AUTOSAR XML (schema 314)
package /ComponentType
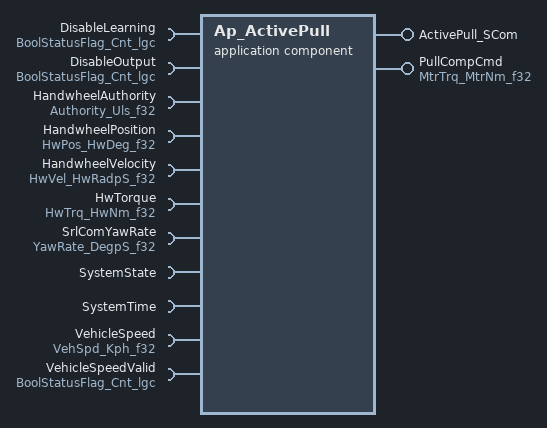
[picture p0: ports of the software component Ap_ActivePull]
  application software component type Ap_ActivePull
    provide port ActivePull_SCom: provided-interface=ActivePull_SCom
      provided-com-specs:
        operation=ReadParam, queue-length=1
        operation=Reset, queue-length=1
        operation=SetLTComp, queue-length=1
        operation=SetSTComp, queue-length=1
    provide port PullCompCmd: unqueued-sender-com-spec{data-element=MtrNm_f32, can-invalidate=false, init-value=D_ZERO_ULS_F32}, provided-interface=MtrTrq_MtrNm_f32
    11 x require port:
      DisableLearning: unqueued-receiver-com-spec{data-element=Cnt_lgc, init-value=D_FALSE_CNT_LGC}, required-interface=BoolStatusFlag_Cnt_lgc
      DisableOutput: unqueued-receiver-com-spec{data-element=Cnt_lgc, init-value=D_FALSE_CNT_LGC}, required-interface=BoolStatusFlag_Cnt_lgc
      HandwheelAuthority: unqueued-receiver-com-spec{data-element=Uls_f32, init-value=D_ZERO_ULS_F32}, required-interface=Authority_Uls_f32
      HandwheelPosition: unqueued-receiver-com-spec{data-element=HwDeg_f32, init-value=D_ZERO_ULS_F32}, required-interface=HwPos_HwDeg_f32
      HandwheelVelocity: unqueued-receiver-com-spec{data-element=HwRadpS_f32, init-value=D_ZERO_ULS_F32}, required-interface=HwVel_HwRadpS_f32
      HwTorque: unqueued-receiver-com-spec{data-element=HwNm_f32, init-value=D_ZERO_ULS_F32}, required-interface=HwTrq_HwNm_f32
      SrlComYawRate: unqueued-receiver-com-spec{data-element=DegpS_f32, init-value=D_ZERO_ULS_F32}, required-interface=YawRate_DegpS_f32
      SystemState: required-interface=SystemState
      SystemTime: required-interface=SystemTime
        required-com-specs:
          DtrmnElapsedTime_mS_u16
          DtrmnElapsedTime_mS_u32
          DtrmnElapsedTime_uS_u16
          DtrmnElapsedTime_uS_u32
          GetSystemTime_mS_u32
          GetSystemTime_uS_u32
      VehicleSpeed: unqueued-receiver-com-spec{data-element=Kph_f32, init-value=D_ZERO_ULS_F32}, required-interface=VehSpd_Kph_f32
      VehicleSpeedValid: unqueued-receiver-com-spec{data-element=Cnt_lgc, init-value=D_FALSE_CNT_LGC}, required-interface=BoolStatusFlag_Cnt_lgc
  internal behavior Ap_ActivePull_InternalBehavior: component=Ap_ActivePull
    4 x timing event:
      ActivePull_Init1_InitEvent: start-on-event=ActivePull_Init1, period=0
      TMT_ActivePull_Per1: mode-dependency=dependent-on-mode=[SystemState.Mode.DISABLE, SystemState.Mode.OFF, SystemState.Mode.WARMINIT], start-on-event=ActivePull_Per1, period=0.002
      TMT_ActivePull_Per2: mode-dependency=dependent-on-mode=SystemState.Mode.OFF, start-on-event=ActivePull_Per2, period=0.002
      TMT_ActivePull_Per3: mode-dependency=dependent-on-mode=[SystemState.Mode.DISABLE, SystemState.Mode.OFF, SystemState.Mode.WARMINIT], start-on-event=ActivePull_Per3, period=0.1
    4 x operation invoked event:
      OIT_ActivePull_SCom_ReadParam_ActivePull_SCom_ReadParam: start-on-event=ActivePull_SCom_ReadParam, operation=ActivePull_SCom.ReadParam
      OIT_ActivePull_SCom_Reset_ActivePull_SCom_Reset: start-on-event=ActivePull_SCom_Reset, operation=ActivePull_SCom.Reset
      OIT_ActivePull_SCom_SetLTComp_ActivePull_SCom_SetLTComp: start-on-event=ActivePull_SCom_SetLTComp, operation=ActivePull_SCom.SetLTComp
      OIT_ActivePull_SCom_SetSTComp_ActivePull_SCom_SetSTComp: start-on-event=ActivePull_SCom_SetSTComp, operation=ActivePull_SCom.SetSTComp
    mode switch event MST_ActivePull_Trns1_0: start-on-event=ActivePull_Trns1, activation=ENTRY, mode=SystemState.Mode.OPERATE
    port-api-options:
      enable-take-address=false, indirect-api=false, port=ActivePull_SCom
      enable-take-address=false, indirect-api=false, port=DisableLearning
      enable-take-address=false, indirect-api=false, port=DisableOutput
      enable-take-address=false, indirect-api=false, port=HandwheelAuthority
      enable-take-address=false, indirect-api=false, port=HandwheelPosition
      enable-take-address=false, indirect-api=false, port=HandwheelVelocity
      enable-take-address=false, indirect-api=false, port=HwTorque
      enable-take-address=false, indirect-api=false, port=PullCompCmd
      enable-take-address=false, indirect-api=false, port=SrlComYawRate
      enable-take-address=false, indirect-api=false, port=SystemState
      enable-take-address=false, indirect-api=false, port=SystemTime
      enable-take-address=false, indirect-api=false, port=VehicleSpeed
      enable-take-address=false, indirect-api=false, port=VehicleSpeedValid
    9 x runnable:
      ActivePull_Init1
      ActivePull_Per1
        9 x data read access:
          READ_DisableLearning_Cnt_lgc: data-element=DisableLearning.Cnt_lgc
          READ_DisableOutput_Cnt_lgc: data-element=DisableOutput.Cnt_lgc
          READ_HandwheelAuthority_Uls_f32: data-element=HandwheelAuthority.Uls_f32
          READ_HandwheelPosition_HwDeg_f32: data-element=HandwheelPosition.HwDeg_f32
          READ_HandwheelVelocity_HwRadpS_f32: data-element=HandwheelVelocity.HwRadpS_f32
          READ_HwTorque_HwNm_f32: data-element=HwTorque.HwNm_f32
          READ_SrlComYawRate_DegpS_f32: data-element=SrlComYawRate.DegpS_f32
          READ_VehicleSpeed_Kph_f32: data-element=VehicleSpeed.Kph_f32
          READ_VehicleSpeedValid_Cnt_lgc: data-element=VehicleSpeedValid.Cnt_lgc
        sync call SC_SystemTime_DtrmnElapsedTime_mS_u32: operation=SystemTime.DtrmnElapsedTime_mS_u32, timeout=0
        sync call SC_SystemTime_GetSystemTime_mS_u32: operation=SystemTime.GetSystemTime_mS_u32, timeout=0
      ActivePull_Per2
        data read access READ_DisableOutput_Cnt_lgc: data-element=DisableOutput.Cnt_lgc
        data read access READ_VehicleSpeed_Kph_f32: data-element=VehicleSpeed.Kph_f32
        data write access WRITE_PullCompCmd_MtrNm_f32: data-element=PullCompCmd.MtrNm_f32
      ActivePull_Per3
        data read access READ_HwTorque_HwNm_f32: data-element=HwTorque.HwNm_f32
        data read access READ_VehicleSpeed_Kph_f32: data-element=VehicleSpeed.Kph_f32
      ActivePull_SCom_ReadParam
      ActivePull_SCom_Reset
      ActivePull_SCom_SetLTComp
      ActivePull_SCom_SetSTComp
      ActivePull_Trns1
        sync call SC_SystemTime_GetSystemTime_mS_u32: operation=SystemTime.GetSystemTime_mS_u32, timeout=0
  swc implementation Ap_ActivePull_Implementation: behavior=Ap_ActivePull_InternalBehavior
    code-descriptors:
      code Code: type=SRC
